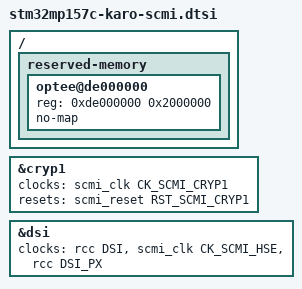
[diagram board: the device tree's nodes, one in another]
// SPDX-License-Identifier: (GPL-2.0-or-later OR BSD-3-Clause)
/*
 * Copyright (C) 2024 Lothar Waßmann <LW@KARO-electronics.de>
 *
 * based on: stm32mp517c-dk2-scmi.dtsi
 *     Copyright (C) STMicroelectronics 2022 - All Rights Reserved
 *     Authot: Alexandre Torgue <alexandre.torgue@foss.st.com> for STMicroelectronics.
 */

#include "stm32mp153a-karo-scmi.dtsi"

/ {
	reserved-memory {
		optee@de000000 {
			reg = <0xde000000 0x2000000>;
			no-map;
		};
	};
};

&cryp1 {
	clocks = <&scmi_clk CK_SCMI_CRYP1>;
	resets = <&scmi_reset RST_SCMI_CRYP1>;
};

&dsi {
	clocks = <&rcc DSI>, <&scmi_clk CK_SCMI_HSE>, <&rcc DSI_PX>;
};
